# SGX530 register map
Vendor: Texas Instruments
Peripheral module from a debugger description file (folder am335x).
Registers are 32-bit, read-write, no defined reset value unless marked. A register's access mark holds for its fields unless they carry their own. Offsets are as the file gives them; lines under a group give offsets from that group; [hi:lo] are bit positions; {n}, {i} and the like mark numbered series; 'fields as' and 'values as' point back to an identical list; <NAME> marks a mode.

## SGX530 (part 1 of 2)
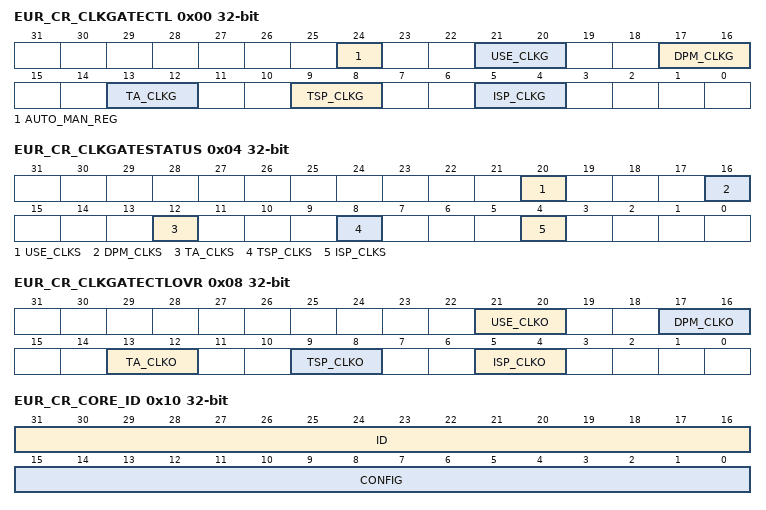
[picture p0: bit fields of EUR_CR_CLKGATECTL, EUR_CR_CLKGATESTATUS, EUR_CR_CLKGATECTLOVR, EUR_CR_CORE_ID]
0x00 EUR_CR_CLKGATECTL — Core module clock gating controls: allows clocks to be forced off, forced on or operate under automatic pipeline activity based clock gating.
  [24] AUTO_MAN_REG — Automatic Register Power Management Control
    0=Register updates automatically turn on clock domains; 1=Manual clock domain control for register updates
  [21:20] USE_CLKG — Clock gating control for the USSE
    0=Gated (Clock gating is active and no clock is supplied to the USSE); 1=Running (Clock to the USSE is enabled); 2=Automatic gating is active, the USSE clock is only active whilst data is being processed
  [17:16] DPM_CLKG — Clock gating control for the DPM
    0=Gated (Clock gating is active and no clock is supplied to the DPM); 1=Running (Clock to the DPM is enabled); 2=Automatic gating is active, the DPM clock is only active whilst data is being processed
  [13:12] TA_CLKG — Clock gating control for the TA
    0=Gated (Clock gating is active and no clock is supplied to the TA); 1=Running (Clock to the TA is enabled); 2=Automatic gating is active, the TA clock is only active whilst data is being processed
  [9:8] TSP_CLKG — Clock gating control for the TSP
    0=Gated (Clock gating is active and no clock is supplied to the TSP); 1=Running (Clock to the TSP is enabled); 2=Automatic gating is active, the TSP clock is only active whilst data is being processed
  [5:4] ISP_CLKG — Clock gating control for the ISP
    0=Gated (Clock gating is active and no clock is supplied to the ISP); 1=Running (Clock to the ISP is enabled); 2=Automatic gating is active, the ISP clock is only active whilst data is being processed
0x04 EUR_CR_CLKGATESTATUS ro — Clock Gating Status reflects the condition of the clock gate controls for each module.
  [20] USE_CLKS — Status of the USSE clock
    0=USSE (USSE clock is gated and the module is inactive); 1=Clock to the USSE is running
  [16] DPM_CLKS — Status of the DPM clock
    0=DPM (DPM clock is gated and the module is inactive); 1=Clock to the DPM is running
  [12] TA_CLKS — Status of the TA clock
    0=TA (TA clock is gated and the module is inactive); 1=Clock to the TA is running
  [8] TSP_CLKS — Status of the TSP clock
    0=TSP (TSP clock is gated and the module is inactive); 1=Clock to the TSP is running
  [4] ISP_CLKS — Status of the ISP clock
    0=ISP (ISP clock is gated and the module is inactive); 1=Clock to the ISP is running
0x08 EUR_CR_CLKGATECTLOVR — Core module clock gating override controls: allows clocks to be enabled temporarily for register writes by hosts.
  [21:20] USE_CLKO — Clock gating control override for the USSE
    1=Enabled (Host enable clock to the USSE request); 3=Disabled (Host disable clock to USSE request. USSE clock may be gated if not other outstanding host requests.)
  [17:16] DPM_CLKO — Clock gating control override for the DPM
    1=Enabled (Clock to the DPM is enabled); 3=Disabled (Host disable clock to DPM request. DPM clock may be gated if not other outstanding host requests.)
  [13:12] TA_CLKO — Clock gating control override for the TA
    1=Enabled (Clock to the TA is enabled); 3=Disabled (Host disable clock to TA request. TA clock may be gated if not other outstanding host requests.)
  [9:8] TSP_CLKO — Clock gating control override for the TSP
    1=Enabled (Clock to the TSP is enabled); 3=Disabled (Host disable clock to TSP request. TSP clock may be gated if no other outstanding host requests.)
  [5:4] ISP_CLKO — Clock gating control override for the ISP
    1=Enabled (Clock to the ISP is enabled); 3=Disabled (Host disable clock to ISP request. ISP clock may be gated if no other outstanding host requests.)
0x10 EUR_CR_CORE_ID ro — Core ID Register
  [31:16] ID — Core ID
  [15:0] CONFIG — Core Configuration
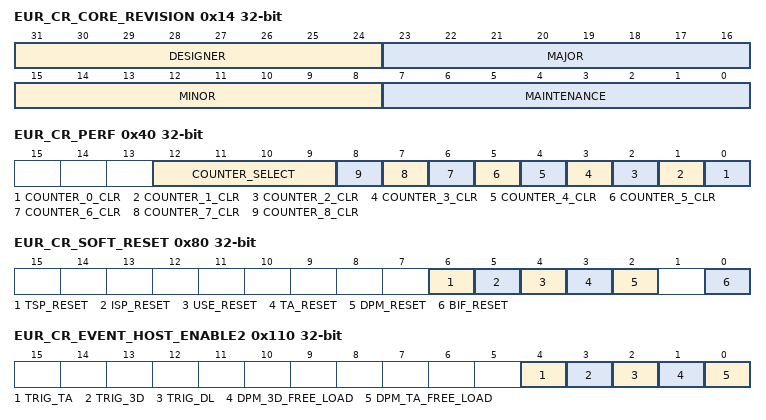
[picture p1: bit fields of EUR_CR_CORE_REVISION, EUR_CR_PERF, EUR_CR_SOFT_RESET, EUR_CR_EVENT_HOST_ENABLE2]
0x14 EUR_CR_CORE_REVISION ro — Core Revision Register identifies the specific core revision. This is updated to reflect the formal release status of the core.
  [31:24] DESIGNER
  [23:16] MAJOR — Major Revision
  [15:8] MINOR — Minor Revision
  [7:0] MAINTENANCE — Maintenance Revision
0x18 EUR_CR_DESIGNER_REV_FIELD1 ro — Designer Revision Field. The SOC designer can use this register for their own revision control if required.
  [31:0] DESIGNER_REV_FIELD1 — Designer Field
0x1C EUR_CR_DESIGNER_REV_FIELD2 ro — Designer Revision Field The SOC designer can use this register for their own revision control if required.
  [31:0] DESIGNER_REV_FIELD2 — Designer Field
0x40 EUR_CR_PERF — Within SGX there are a number of performance counters which enable profiling of an application in terms of the low level hardware performance; this register enables selection of specific groups of performance counters and the ability to reset those counters. Full details can be found in the performance profiling section of this document. Write a '1' followed by a '0' to the _CLR fields to reset the specific counter
  [12:9] COUNTER_SELECT — 0x0 Core Overview counter group. Default value is set to 0xF, no counter will be in operation
    1=Primitive Clipping counter group; 2=Scene Buffer counter group; 3=ISP (ISP counter group); 4=TSP (TSP counter group); 5=USE (USE counter group); 6=Texturing counter group; 9=Core Overview 2 counter group
  [n] COUNTER_{n}_CLR (n=0..8) — Reset counter = '1', normal counter operation '0'
{0x44+4i} EUR_CR_PERF_COUNTER{i} ro (i=0..7) — Performance counter {i} status register
  [31:0] COUNTER{i} — 32 bit integer count value, see performance profiling section for details
0x64 EUR_CR_PERF_COUNTER8 ro — Performance counter status register
  [31:0] COUNTER8 — 32 bit integer count value, see performance profiling section for details
0x80 EUR_CR_SOFT_RESET — Soft reset control register which drives all modules except the register bank. Write a '1' to reset and a '0' to clear
  [6] TSP_RESET — TSP soft reset control field
  [5] ISP_RESET — ISP soft reset control field
  [4] USE_RESET — USE soft reset control field
  [3] TA_RESET — TA soft reset control field
  [2] DPM_RESET — DPM soft reset control field
  [0] BIF_RESET — BIF soft reset control field
0x100 EUR_CR_TRIGGER — TA/3D Lockup counter timeout value (16K cycle granularity) (Debug only, for further information contact Imagination Technologies)
  [4:0] TRIGGER_COUNT — Trigger count value in 16K cycles for TA and 3D lockup triggers
0x110 EUR_CR_EVENT_HOST_ENABLE2 — This register enables interrupts. Writing a '1' to a bit field enables the relevant Event. All the bit fields correspond exactly to those in the EUR_CR_EVENT_STATUS2 register. The MASTER_INTERRUPT bit is a global enable which overrides the Event enables, i.e. '1' - enable external interrupts, '0' - disable external interrupts.
  [4] TRIG_TA — Host_Enable: Lockup in TA Phase Trigger
  [3] TRIG_3D — Host_Enable: Lockup in 3d Phase Trigger
  [2] TRIG_DL — Host_Enable: Deadlock has occurred after a Partial Render
  [1] DPM_3D_FREE_LOAD — Host_Enable: DPM 3D Free Load task complete
  [0] DPM_TA_FREE_LOAD — Host_Enable: DPM TA Free Load task complete
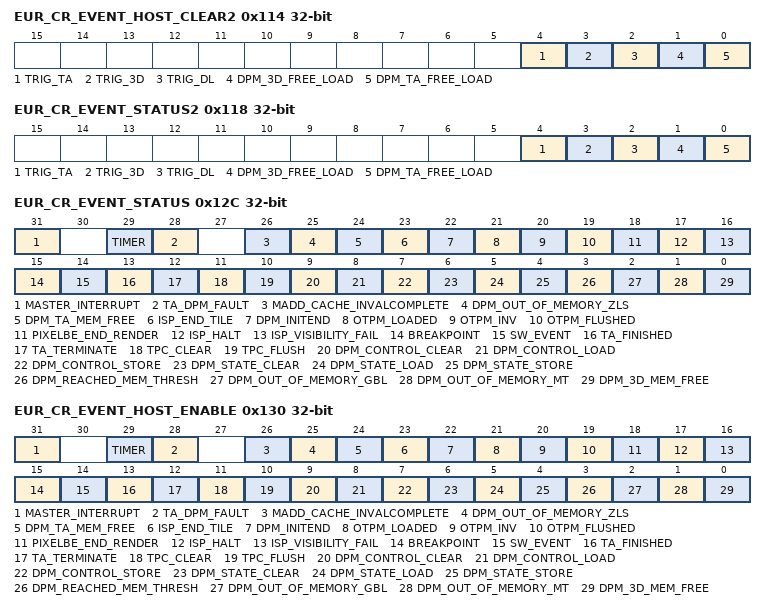
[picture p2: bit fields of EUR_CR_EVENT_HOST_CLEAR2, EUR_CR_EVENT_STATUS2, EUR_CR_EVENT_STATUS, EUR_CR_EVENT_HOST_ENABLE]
0x114 EUR_CR_EVENT_HOST_CLEAR2 wo — This register is used to clear event interrupts. Writing a '1' to a bit field clears the relevant Event. All the bit fields correspond exactly to those in the EUR_CR_EVENT_STATUS2 register.
  [4] TRIG_TA — Host_Clear: Lockup in TA Phase Trigger
  [3] TRIG_3D — Host_Clear: Lockup in 3d Phase Trigger
  [2] TRIG_DL — Host_Clear: Deadlock has occurred after a Partial Render
  [1] DPM_3D_FREE_LOAD — Host_Clear: DPM 3D Free Load task complete
  [0] DPM_TA_FREE_LOAD — Host_Clear: DPM TA Free Load task complete
0x118 EUR_CR_EVENT_STATUS2 — There are 2 sources of external interrupts in the PowerVR SGX core: General system events and PDS cache invalidation events. The event status2 register indicates the source of any general event interrupt generated by PowerVR SGX. These events only result in an external interrupt if the relevant bit in the EUR_CR_EVENT_HOST_ENABLE register is set. Note1: This register must be combined with the EUR_CR_PDS_CACHE_STATUS register information to determine what has caused the external interrupt. Note2: The host can write to this register in which case any bits written as a '1' are ORed into the register i.e. the host can cause the core to generate an interrupt. (This is typically for debug purposes only)
  [4] TRIG_TA — Status: Lockup in TA Phase Trigger
  [3] TRIG_3D — Status: Lockup in 3d Phase Trigger
  [2] TRIG_DL — Status: Deadlock has occurred after a Partial Render
  [1] DPM_3D_FREE_LOAD — Status: DPM 3D free load task complete
  [0] DPM_TA_FREE_LOAD — Status: DPM TA free load task complete
0x12C EUR_CR_EVENT_STATUS — There are 2 sources of external interrupts in the PowerVR SGX core: General system events and PDS cache invalidation events. The event status register indicates the source of any general event interrupt generated by PowerVR SGX. These events only result in an external interrupt if the relevant bit in the EUR_CR_EVENT_HOST_ENABLE register is set. Note1: This register must be combined with the EUR_CR_PDS_CACHE_STATUS register information to determine what has caused the external interrupt. Note2: The host can write to this register in which case any bits written as a '1' are ORed into the register i.e. the host can cause the core to generate an interrupt. (This is typically for debug purposes only)
  [31] MASTER_INTERRUPT — Status: PowerVR SGX Master Interrupt Control
  [29] TIMER — Status: The PDS Event timer interrupt (signalled on timer traversing through 0).
  [28] TA_DPM_FAULT — Status: The TA Object Passing System has got out of sync, a Terminate Control Word DPM read was met by StartofBlock data
  [26] MADD_CACHE_INVALCOMPLETE — Status: Invalidate of Madd L0, L1, L2 Cache Complete
  [25] DPM_OUT_OF_MEMORY_ZLS — Status: Memory Allocation Failed for ZLS
  [24] DPM_TA_MEM_FREE — Status: All memory associated with TA context has been freed
  [23] ISP_END_TILE — Status: ISP End tile
  [22] DPM_INITEND — Status: DPM Initialisation Complete
  [21] OTPM_LOADED — Status: The OTPM has loaded its state
  [20] OTPM_INV — Status: The OTPM has invalidated its contents
  [19] OTPM_FLUSHED — Status: The OTPM has flushed its state
  [18] PIXELBE_END_RENDER — Status: End of Scene
  [17] ISP_HALT — Status: ISP Halt breakpoint triggered
  [16] ISP_VISIBILITY_FAIL — Status: Visibility Test Fail
  [15] BREAKPOINT — Status: ISP Breakpoint
  [14] SW_EVENT — Status: Software triggered event
  [13] TA_FINISHED — Status: TA complete - This is set and held high after the TE terminates scene, until TA is restarted
  [12] TA_TERMINATE — Status: The TA terminate complete (issue as part of complex scene) - This is set and held high after the TE aborts a MacroTile after failed DPM allocation request, until TA is restarted
  [11] TPC_CLEAR — Status: The TPC has reset its state
  [10] TPC_FLUSH — Status: The TPC has stored its state
  [9] DPM_CONTROL_CLEAR — Status: The reset of the DPM control context has been completed
  [8] DPM_CONTROL_LOAD — Status: The load of the DPM control context has been completed
  [7] DPM_CONTROL_STORE — Status: The store of the DPM control context has been completed
  [6] DPM_STATE_CLEAR — Status: The reset of the DPM state context has been completed
  [5] DPM_STATE_LOAD — Status: The load of the DPM state context has been completed
  [4] DPM_STATE_STORE — Status: The store of the DPM state context has been completed
  [3] DPM_REACHED_MEM_THRESH — Status: DPM Memory allocation has reached the preset memory threshold for total memory allocation
  [2] DPM_OUT_OF_MEMORY_GBL — Status: DPM Memory allocation failed for the global list
  [1] DPM_OUT_OF_MEMORY_MT — Status: DPM Memory allocation failed for a macro tile
  [0] DPM_3D_MEM_FREE — Status: DPM Memory allocation complete for the current render
0x130 EUR_CR_EVENT_HOST_ENABLE — This register enables interrupts. Writing a '1' to a bit field enables the relevant Event. All the bit fields correspond exactly to those in the EUR_CR_EVENT_STATUS register. The MASTER_INTERRUPT bit is a global enable which overrides the Event enables, i.e. '1' - enable external interrupts, '0' - disable external interrupts.
  [31] MASTER_INTERRUPT — Host_Enable: PowerVR SGX Master Interrupt Control
  [29] TIMER — Host_Enable: The PDS Event timer interrupt (signalled on timer traversing through 0).
  [28] TA_DPM_FAULT — Host_Enable: The Tiling Co-Processor Object Passing System has got out of sync, a Terminate Control Word DPM read was met by StartofBlock data
  [26] MADD_CACHE_INVALCOMPLETE — Host_Enable: Invalidate of Madd L0, L1, L2 Cache Complete
  [25] DPM_OUT_OF_MEMORY_ZLS — Host_Enable: Memory Allocation Failed for ZLS
  [24] DPM_TA_MEM_FREE — Host_Enable: All memory associated with TA context has been freed
  [23] ISP_END_TILE — Host_Enable: ISP End tile
  [22] DPM_INITEND — Host_Enable: DPM Initialisation Complete
  [21] OTPM_LOADED — Host_Enable: The OTPM has loaded its state
  [20] OTPM_INV — Host_Enable: The OTPM has invalidated its contents
  [19] OTPM_FLUSHED — Host_Enable: The OTPM has flushed its state
  [18] PIXELBE_END_RENDER — Host_Enable: End of Scene
  [17] ISP_HALT — Host_Enable: ISP Halt breakpoint triggered
  [16] ISP_VISIBILITY_FAIL — Host_Enable: Visibility Test Fail
  [15] BREAKPOINT — Host_Enable: ISP Breakpoint
  [14] SW_EVENT — Host_Enable: Software triggered event
  [13] TA_FINISHED — Host_Enable: Tiling Co-Processor complete, (Scene Terminated)
  [12] TA_TERMINATE — Host_Enable: The Tiling Co-Processor terminate complete (issue as part of complex scene) (MacroTile Aborted)
  [11] TPC_CLEAR — Host_Enable: The TPC has reset its state
  [10] TPC_FLUSH — Host_Enable: The TPC has stored its state
  [9] DPM_CONTROL_CLEAR — Host_Enable: The reset of the DPM control context has been completed
  [8] DPM_CONTROL_LOAD — Host_Enable: The load of the DPM control context has been completed
  [7] DPM_CONTROL_STORE — Host_Enable: The store of the DPM control context has been completed
  [6] DPM_STATE_CLEAR — Host_Enable: The reset of the DPM state context has been completed
  [5] DPM_STATE_LOAD — Host_Enable: The load of the DPM state context has been completed
  [4] DPM_STATE_STORE — Host_Enable: The store of the DPM state context has been completed
  [3] DPM_REACHED_MEM_THRESH — Host_Enable: DPM Memory allocation has reached the preset memory threshold for total memory allocation
  [2] DPM_OUT_OF_MEMORY_GBL — Host_Enable: DPM Memory allocation failed for the global list
  [1] DPM_OUT_OF_MEMORY_MT — Host_Enable: DPM Memory allocation failed for a macro tile
  [0] DPM_3D_MEM_FREE — Host_Enable: DPM Memory allocation complete for the current render
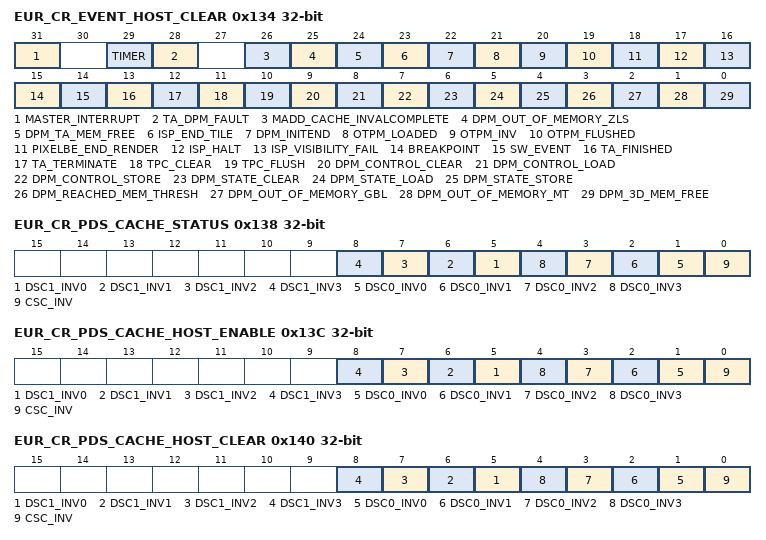
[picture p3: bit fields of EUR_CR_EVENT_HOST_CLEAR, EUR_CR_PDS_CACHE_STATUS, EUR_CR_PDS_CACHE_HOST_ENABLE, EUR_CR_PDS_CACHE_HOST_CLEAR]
0x134 EUR_CR_EVENT_HOST_CLEAR — This register is used to clear event interrupts. Writing a '1' to a bit field clears the relevant Event. All the bit fields correspond exactly to those in the EUR_CR_EVENT_STATUS register.
  [31] MASTER_INTERRUPT — Host_Clear: PowerVR SGX Master Interrupt
  [29] TIMER — Host_Clear: The PDS Event timer interrupt (signalled on timer traversing through 0).
  [28] TA_DPM_FAULT — Host_Clear: The TA Object Passing System has got out of sync, a Terminate Control Word DPM read was met by StartofBlock data
  [26] MADD_CACHE_INVALCOMPLETE — Host_Clear: Invalidate of Madd L1, L2 Cache Complete
  [25] DPM_OUT_OF_MEMORY_ZLS — Host_Clear: Memory Allocation Failed for ZLS
  [24] DPM_TA_MEM_FREE — Host_Clear: All memory associated with TA context has been freed
  [23] ISP_END_TILE — Host_Clear: ISP End tile
  [22] DPM_INITEND — Host_Clear: DPM Initialisation Complete
  [21] OTPM_LOADED — Host_Clear: The OTPM has loaded its state
  [20] OTPM_INV — Host_Clear: The OTPM has invalidated its contents
  [19] OTPM_FLUSHED — Host_Clear: The OTPM has flushed its state
  [18] PIXELBE_END_RENDER — Host_Clear: End of Scene
  [17] ISP_HALT — Host_Clear: ISP Halt breakpoint triggered
  [16] ISP_VISIBILITY_FAIL — Host_Clear: Visibility Test Fail
  [15] BREAKPOINT — Host_Clear: ISP Breakpoint
  [14] SW_EVENT — Host_Clear: Software triggered event
  [13] TA_FINISHED — Host_Clear: Tiling Co-Processor complete (Scene Terminated)
  [12] TA_TERMINATE — Host_Clear: The Tiling Co-Processor terminate complete (issue as part of complex scene) (MacroTile aborted)
  [11] TPC_CLEAR — Host_Clear: The TPC has reset its state
  [10] TPC_FLUSH — Host_Clear: The TPC has stored its state
  [9] DPM_CONTROL_CLEAR — Host_Clear: The reset of the DPM control context has been completed
  [8] DPM_CONTROL_LOAD — Host_Clear: The load of the DPM control context has been completed
  [7] DPM_CONTROL_STORE — Host_Clear: The store of the DPM control context has been completed
  [6] DPM_STATE_CLEAR — Host_Clear: The reset of the DPM state context has been completed
  [5] DPM_STATE_LOAD — Host_Clear: The load of the DPM state context has been completed
  [4] DPM_STATE_STORE — Host_Clear: The store of the DPM state context has been completed
  [3] DPM_REACHED_MEM_THRESH — Host_Clear: DPM Memory allocation has reached the preset memory threshold for total memory allocation
  [2] DPM_OUT_OF_MEMORY_GBL — Host_Clear: DPM Memory allocation failed for the global list
  [1] DPM_OUT_OF_MEMORY_MT — Host_Clear: DPM Memory allocation failed for a macro tile
  [0] DPM_3D_MEM_FREE — Host_Clear: DPM Memory allocation complete for the current render
0x138 EUR_CR_PDS_CACHE_STATUS — There are 2 sources of external interrupts in the PowerVR SGX core: General system events and PDS cache invalidation events. The PDS cache status register indicates the source of any PDS cache invalidation event interrupts generated by PowerVR SGX. These events only result in an external interrupt if the relevant bit in the EUR_CR_PDS_CACHE_HOST_ENABLE register is set. Note1: This register must be combined with the EUR_CR_EVENT_STATUS register information to determine what has caused the external interrupt. Note2: The host can write to this register in which case any bits written as a '1' are ORed into the register i.e. the host can cause the core to generate an interrupt. (This is typically for debug purposes only)
  [n+5] DSC1_INV{n} (n=0..3) — Status: Context ID {n} has been invalidated in PDS Data Store Cache 1
  [n+1] DSC0_INV{n} (n=0..3) — Status: Context ID {n} has been invalidated in PDS Data Store Cache 0
  [0] CSC_INV — Status: PDS Code Store Cache has been invalidated
0x13C EUR_CR_PDS_CACHE_HOST_ENABLE — This register enables interrupts. Writing a '1' to a bit field enables the relevant Event. All the bit fields correspond exactly to those in the EUR_CR_PDS_CACHE_STATUS register. The MASTER_INTERRUPT bit contained in the EUR_CR_EVENT_HOST_ENABLE register is a global enable which overrides the Event enables, i.e. '1' - enable external interrupts, '0' - disable external interrupts.
  [n+5] DSC1_INV{n} (n=0..3) — Host_Enable: Context ID {n} has been invalidated in PDS Data Store Cache 1
  [n+1] DSC0_INV{n} (n=0..3) — Host_Enable: Context ID {n} has been invalidated in PDS Data Store Cache 0
  [0] CSC_INV — Host_Enable: PDS Code Store Cache has been invalidated
0x140 EUR_CR_PDS_CACHE_HOST_CLEAR — This register is used to clear event interrupts. Writing a '1' to a bit field clears the relevant Event. All the bit fields correspond exactly to those in the EUR_CR_PDS_CACHE_STATUS register.
  [n+5] DSC1_INV{n} (n=0..3) — Host_Clear: Context ID {n} has been invalidated in PDS Data Store Cache 1
  [n+1] DSC0_INV{n} (n=0..3) — Host_Clear: Context ID {n} has been invalidated in PDS Data Store Cache 0
  [0] CSC_INV — Host_Clear: PDS Code Store Cache has been invalidated
0x200 EUR_CR_VDM_START wo — Any write to this register starts the Vertex Data Master DMA operation
  [0] PULSE — Start VDM DMA
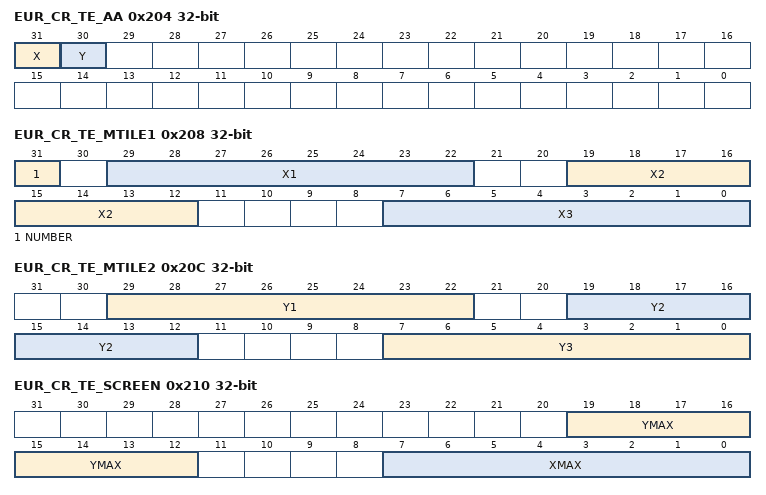
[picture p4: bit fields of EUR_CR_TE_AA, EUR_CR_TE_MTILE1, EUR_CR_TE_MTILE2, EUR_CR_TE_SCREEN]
0x204 EUR_CR_TE_AA — This register controls the anti-aliasing mode of the Tiling Co-Processor, independent control is provided in both X & Y axis.
  [31] X — Anti-Aliasing in X:
    0=No (No Anti-Aliasing on X plane); 1=Yes (Anti-Aliasing on X plane)
  [30] Y — Anti-Aliasing in Y:
    0=No (No Anti-Aliasing on Y plane); 1=Yes (Anti-Aliasing on Y plane)
0x208 EUR_CR_TE_MTILE1 — The Tiling Co-Processor allocates memory in macrotiles, which is a group of individual tiles. The number of macrotiles is selectable between 4 & 16, the boundaries of the macrotiles in the X axis are defined in this register.
  [31] NUMBER — PSG_MacroTile_Number:
    0=4 MacroTiles; 1=16 MacroTiles
  [29:22] X1 — X1 MacroTile boundary, left tile X for second column of macrotiles (16MT mode)
  [19:12] X2 — X2 MacroTile boundary, left tile X for second(4MT)/third(16MT) column of macrotiles
  [7:0] X3 — X3 MacroTile boundary, left tile X for fourth column of macrotiles (16MT)
0x20C EUR_CR_TE_MTILE2 — The Tiling Co-Processor allocates memory in macrotiles, which is a group of individual tiles. The number of macrotiles is selectable between 4 & 16, the boundaries of the macrotiles in the Y axis are defined in this register.
  [29:22] Y1 — Y1 MacroTile boundary, top tile Y for second row of macrotiles (16MT mode)
  [19:12] Y2 — Y2 MacroTile boundary, top tile Y for second(4MT)/third(16MT) row of macrotiles
  [7:0] Y3 — Y1 MacroTile boundary, top tile Y for fourth row of macrotiles (16MT mode)
0x210 EUR_CR_TE_SCREEN — In order to perform the tiling operation and generate the display list the maximum screen size must be configured in terms of the number of tiles in X & Y axis.
  [19:12] YMAX — Maximum Y tile address visible on screen
  [7:0] XMAX — Maximum X tile address visible on screen
0x214 EUR_CR_TE_MTILE — This register defines the number of individual tiles within the macrotiles. This is used in the process of memory allocation.
  [17:0] STRIDE — Number of tiles in a Macrotile. Stride = (XTile * YTiles)
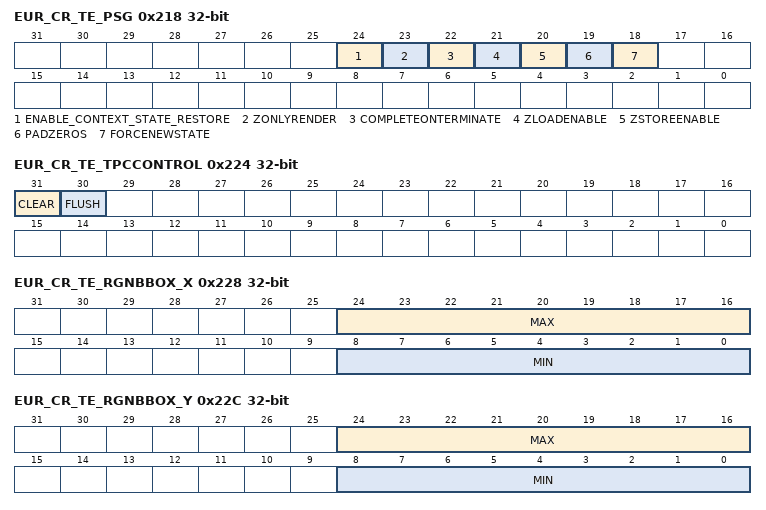
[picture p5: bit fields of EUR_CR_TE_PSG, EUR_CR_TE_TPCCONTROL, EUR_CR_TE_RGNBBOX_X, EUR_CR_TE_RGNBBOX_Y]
0x218 EUR_CR_TE_PSG — This register defines the global control for the Parameter Stream Generator within the Tiling Co-Processor. This module formats the display list generated by the Tiling Co-Processor.
  [24] ENABLE_CONTEXT_STATE_RESTORE — Enables sampling of Driver TE_STATE_ISP_STATE_ID register on context switch/restore when set, when reset current local value is preserved.
  [23] ZONLYRENDER — Don't invalidate Tail Pointer Cache entries on a Terminate command. Only effective when COMPLETEONTERMINATE is 0x0
    0=Do (Do Invalidate); 1=Don (Don't Invalidate)
  [22] COMPLETEONTERMINATE — 0x1 Write region headers, terminate streams and invalidate tail pointer cache entries on terminate.
    0=If (If ZONLYRENDER = 0x0 then force an Interrupt, however if ZONLYRENDER = 0x1 then write region headers and terminate streams.)
  [21] ZLOADENABLE — If 0x1 set the zload enable bit in the region headers. If 0x0 the region header zload bit is controlled by the hardware automatically. The bit is set if a partial render has been performed on that tile.
  [20] ZSTOREENABLE — If 0x1 set the zstore enable bit in the region headers. If 0x0 the region header zstore bit is controlled by the hardware automatically. The bit is set if a partial render is about to be performed on that tile.
  [19] PADZEROS — Pad empty doublewords in allocation with zeros after Stream Link/Terminate. The allocation block size is 16 DWords, so potentially inserts 13 extra DWords of zeros into a pointer block. Debug only. Makes examination of memory more readable on a per frame basis.
  [18] FORCENEWSTATE — Always embed state information in control stream. Debug only.
0x21C EUR_CR_TE_PSGREGION_BASE — This register defines the base address in memory of the Region Header writes by the TA. Region headers are the first part of the display list and contain an entry per tile with information on global setup and a link address to parameters.
  [27:6] ADDR — 256MB Addressable, 512-bit aligned Base Address for Region Header writes
0x220 EUR_CR_TE_TPC_BASE — This register defines the base address in memory of the Tail Pointer Cache. A tail pointer is the current last address written to for a tiles individual display list, an entry for active tiles is maintained as primitives are processed by the TA.
  [27:6] ADDR — 256MB Addressable, 512-bit aligned Base Address for Tail Pointer Cache. The tail pointer is the current last address written to for a control stream for a tile.
0x224 EUR_CR_TE_TPCCONTROL wo — The Tail Pointer Cache is used to keep track of the last address written to for a particular tile, this is stored in a mixture of on chip cache and external memory. Under certain circumstances it is necessary to either reset the cache or flush the on chip cache contents such that they are visible in memory.
  [31] CLEAR — Reset contents of Tail Pointer Cache
  [30] FLUSH — Flush contents of Tail Pointer Cache to Memory
0x228 EUR_CR_TE_RGNBBOX_X ro — Reset or enabled by the MTE_RESETBBOX and MTE_UPDATEBBOX fields in the MTEControl word of the Input Parameter format. This is the maximum extent in X of the post transformed, clipped data before region clipping.
  [24:16] MAX — XMax value for maintained Region Generator Bounding Box
  [8:0] MIN — XMin value for maintained Region Generator Bounding Box
0x22C EUR_CR_TE_RGNBBOX_Y ro — Reset or enabled by the MTE_RESETBBOX and MTE_UPDATEBBOX fields in the MTE Control word of the Input Parameter format. This is the maximum extent in Y of the post transformed, clipped data before region clipping.
  [24:16] MAX — YMax value for maintained Region Generator Bounding Box
  [8:0] MIN — YMin value for maintained Region Generator Bounding Box
0x230 EUR_CR_MTE_OTPM_CSM_FLUSH_BASE — The TA maintains internal state of the current information for each macro tile and global list regarding the vertex blocks written to memory. In certain circumstances during a context switch it is necessary to flush this information to external memory.
  [27:4] ADDR — 256MB Addressable, 512-bit aligned Base Address for Object Tail Pointer Memory Context Switchable Memory (OTPM CSM) Flush. This is the current point for each macro tile and global list, for the vertex blocks written to memory by the Tile Accelerator.
0x234 EUR_CR_MTE_OTPM_CSM_LOAD_BASE — The TA maintains internal state of the current information for each macro tile and global list regarding the vertex blocks written to memory. In certain circumstances during a context switch it is necessary to load this information from external memory.
  [27:4] ADDR — 256MB Addressable, 512-bit aligned Base Address for Object Tail Pointer Memory Context Switchable Memory (OTPM CSM) Load. This is the current point for each macro tile and global list, for the vertex blocks written to memory by the Tile Accelerator.
0x238 EUR_CR_VDM_CTRL_STREAM_BASE — PowerVR SGX masters information from memory using advanced DMA, this register defines the base address of the Vertex Data input control stream in memory.
  [27:2] ADDR — 256MB Addressable, byte aligned Base Address for Vertex Data control streams
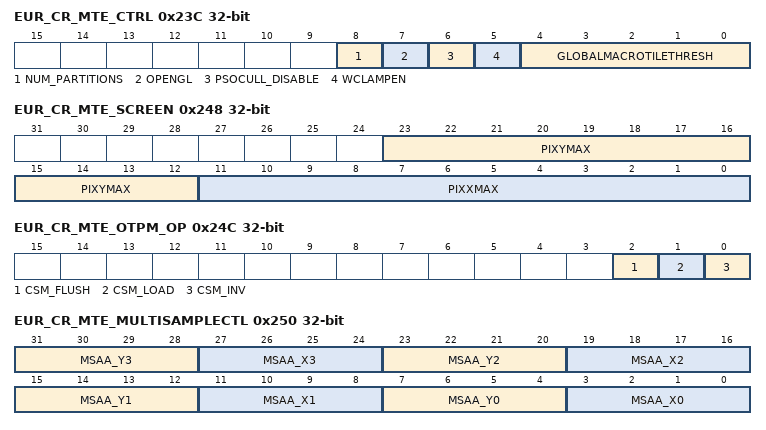
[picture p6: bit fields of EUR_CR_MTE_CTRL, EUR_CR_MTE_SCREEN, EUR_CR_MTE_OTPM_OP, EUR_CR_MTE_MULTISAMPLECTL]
0x23C EUR_CR_MTE_CTRL — This register controls the global setup of the Tiling Process.
  [8] NUM_PARTITIONS — Maximum number of partitions which can be used per USSE pipeline:
    0=Two; 1=Four
  [7] OPENGL — Select OpenGL or D3D mode
    0=D3D; 1=OpenGL
  [6] PSOCULL_DISABLE — Disable for perfect small object culling
    0=en (Perfect small object culling enabled); 1=dis (Perfect small object culling disabled)
  [5] WCLAMPEN — Enable W clamping
    0=dis (W clamping disabled); 1=en (W clamping enabled)
  [4:0] GLOBALMACROTILETHRESH — When writing to global list, number of primitives which are within the same macrotile before the macrotile calculation will change from global.
0x240 EUR_CR_MTE_WCOMPARE
  [31:0] VALUE — Compare value for W clamping. See the Input parameter format, viewport transform for details. Compare is applied post viewport transform.
0x244 EUR_CR_MTE_WCLAMP
  [31:0] VALUE — Clamp value for W clamping. See the Input parameter format, viewport transform for details. Clamp is applied post viewport transform, if the w value is less than the WCOMPARE value.
0x248 EUR_CR_MTE_SCREEN — In order to perform the tiling operation and generate the display list the maximum screen size must be configured in terms of the number of pixels in X & Y axis since this may not be the same as the number of tiles defined in the EUR_CR_TE_SCREEN register.
  [23:12] PIXYMAX — Screen height in pixels.
  [11:0] PIXXMAX — Screen width in pixels.
0x24C EUR_CR_MTE_OTPM_OP wo — The TA maintains internal state of the current information for each macro tile and global list regarding the vertex blocks written to memory. In certain circumstances during a context switch it is necessary to load or flush this information to external memory.
  [2] CSM_FLUSH — Flush CSM contents to CSM Flush Address
  [1] CSM_LOAD — Load CSM contents from CSM Load Address
  [0] CSM_INV — Invalidate CSM contents
0x250 EUR_CR_MTE_MULTISAMPLECTL — This applies when anti-aliasing is enabled. This is used to calculate whether an anti-aliased triangle can be perfect small object culled.
  [31:28] MSAA_Y3 — Unsigned sub-pixel offset for the 4th multisample Y position
  [27:24] MSAA_X3 — Unsigned sub-pixel offset for the 4th multisample X position
  [23:20] MSAA_Y2 — Unsigned sub-pixel offset for the 3rd multisample Y position
  [19:16] MSAA_X2 — Unsigned sub-pixel offset for the 3rd multisample X position
  [15:12] MSAA_Y1 — Unsigned sub-pixel offset for the 2nd multisample Y position
  [11:8] MSAA_X1 — Unsigned sub-pixel offset for the 2nd multisample X position
  [7:4] MSAA_Y0 — Unsigned sub-pixel offset for the 1st multisample Y position
  [3:0] MSAA_X0 — Unsigned sub-pixel offset for the 1st multisample X position
0x26C EUR_CR_MTE_SIG1 ro
  [31:0] TE_SIGNATURE — Signature of output to TE. A signature is an accumulative LFSR (Linear Feedback Shift Register) of the valid pipeline data using an XOR structure.
0x270 EUR_CR_MTE_SIG2 ro
  [31:0] MEM_SIGNATURE — Signature of output to memory. A signature is an accumulative LFSR (Linear Feedback Shift Register) of the valid pipeline data using an XOR structure.
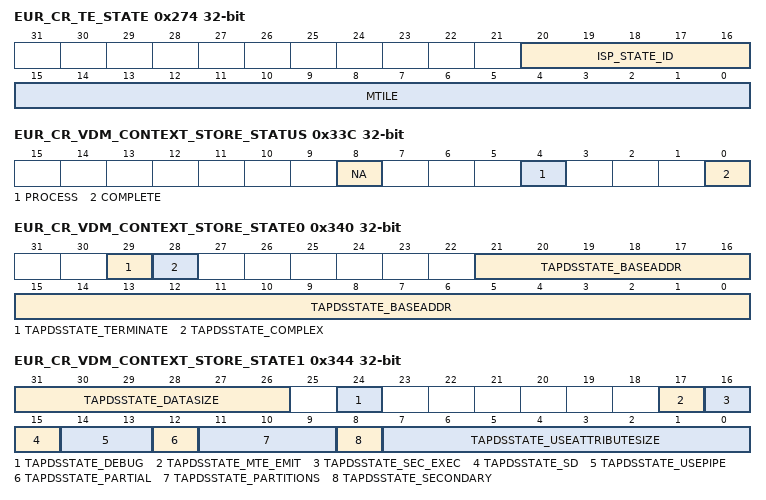
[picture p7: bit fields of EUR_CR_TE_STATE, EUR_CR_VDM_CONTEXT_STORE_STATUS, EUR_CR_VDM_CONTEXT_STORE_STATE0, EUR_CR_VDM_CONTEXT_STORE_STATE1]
0x274 EUR_CR_TE_STATE — This register is read on VDM_START_PULSE and should be saved and updated by the driver app by app
  [20:16] ISP_STATE_ID — This register contains the PSG internal ISP State ID Counter value. It must be saved off by the driver on TA terminate or finished and restored before vdm_start_pulse.
  [15:0] MTILE — A read of this register returns the page allocated to the host, when valid. If it is not valid the return data is undefined.
0x304 EUR_CR_CLIP_SIG1 ro
  [31:0] CLIP_SIGNATURE — Signature of Barycentric vertices output during each clipping pass i.e. clipped against each clip plane in turn. A signature is an accumulative LFSR (Linear Feedback Shift Register) of the valid pipeline data using an XOR structure.
0x308 EUR_CR_PIXELBE_SIG01 ro
  [31:0] SIGNATURE — Signature of data output from PBE to BIF. A signature is an accumulative LFSR (Linear Feedback Shift Register) of the valid pipeline data using an XOR structure.
0x30C EUR_CR_PIXELBE_SIG02 ro
  [31:0] SIGNATURE — Signature of control data output from PBE to BIF. A signature is an accumulative LFSR (Linear Feedback Shift Register) of the valid pipeline data using an XOR structure.
0x330 EUR_CR_VDM_CONTEXT_STORE_START — Start VDM Context store, pulse kicks off the store operation. Status flags when this is complete and the stream and index position registers are valid
  [0] PULSE — Start VDM Context store
0x334 EUR_CR_VDM_CONTEXT_STORE_STREAM ro — Stores the stream position when the context store occured
  [27:2] ADDR — stream position for context store, number of 32bit dwords from a base address update (ie. between stream link or terminates)
0x338 EUR_CR_VDM_CONTEXT_STORE_INDEX ro — Stores the index position when the context store occured
  [21:0] ADDR — Index position for context store, number of index words from an index define
0x33C EUR_CR_VDM_CONTEXT_STORE_STATUS ro — Signals when a context store is complete and the stream and index location registers are valid
  [8] NA — Context store not applicable doing a stream terminate
  [4] PROCESS — Context store processing
  [0] COMPLETE — Context store complete
0x340 EUR_CR_VDM_CONTEXT_STORE_STATE0 — Terminate state control registers used for creating the terminate PDS task.
  [29] TAPDSSTATE_TERMINATE — defines the last word in the control stream, used to generate end ta
  [28] TAPDSSTATE_COMPLEX — defines if the state update is complex
  [21:0] TAPDSSTATE_BASEADDR — Base address (128Bit Aligned, 256 MByte range), in 16 byte units of the PDS code and data to be executed
0x344 EUR_CR_VDM_CONTEXT_STORE_STATE1 — Terminate state control registers used for creating the terminate PDS task.
  [31:26] TAPDSSTATE_DATASIZE — Size of the PDS Data segment in 128 bit words. The data segment always precedes the code segment. 0 = 0x0, Max = 0x20
  [24] TAPDSSTATE_DEBUG — Enables breakpoints on this program
  [17] TAPDSSTATE_MTE_EMIT — If set the USSE will output state to the MTE
  [16] TAPDSSTATE_SEC_EXEC — 0 ' Do not execute secondary task on the USSE/1 ' Execute secondary task on the USSE Has no effect on primary tasks.
  [15] TAPDSSTATE_SD — Indicates a sequential dependency
  [14:13] TAPDSSTATE_USEPIPE — 0 ' Reserved/1 ' Run on pipe 1/2 ' Run on pipe 2/3 ' Run on both pipes
  [12] TAPDSSTATE_PARTIAL — Indicates partial secondary updates.
  [11:9] TAPDSSTATE_PARTITIONS — Number of output partitions required. 0 = 0x0 and Max = 0x4
  [8] TAPDSSTATE_SECONDARY — Indicates that the allocation is secondary
  [7:0] TAPDSSTATE_USEATTRIBUTESIZE — Size of the USSE Attribute Requirements for the task in 128 bit Words
0x348 EUR_CR_VDM_WAIT_FOR_KICK ro — Indicates the status on the control stream fetch
  [0] STATUS — Indicates when state machine is in idle
0x34C EUR_CR_VDM_CONTEXT_STORE_WRAP_INDEX ro — Stores the number of indices since the last wrap
  [21:0] COUNT — Wrap Index Count for context store, number of indices since last wrap
0x350 EUR_CR_VDM_CONTEXT_STORE_WRAPPED ro — Indicates the number of times that index wrapping has occurred after a context store
  [21:0] COUNT — Wrapped count for context store, number of times the hardware has wrapped after a context store
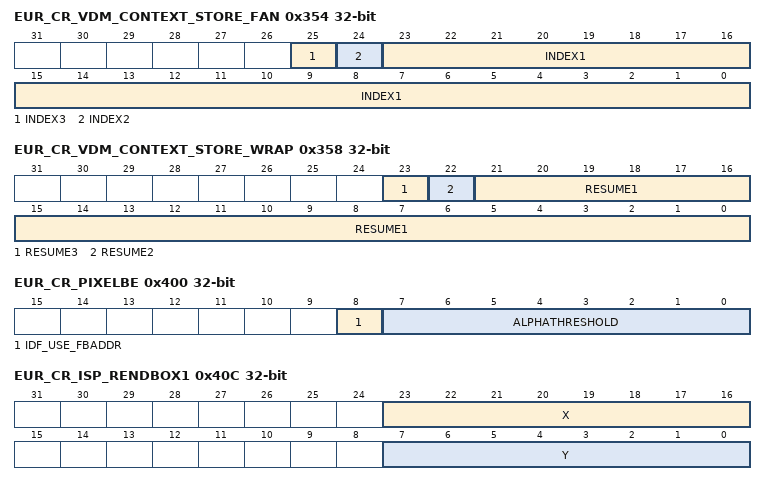
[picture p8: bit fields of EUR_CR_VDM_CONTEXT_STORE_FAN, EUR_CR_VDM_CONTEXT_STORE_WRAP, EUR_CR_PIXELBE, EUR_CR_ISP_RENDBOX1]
0x354 EUR_CR_VDM_CONTEXT_STORE_FAN — The driver sets this register on a context switch such that the hardware can resume knowing where the centre point of a fan is located or the winding order of the strip, expressed as an index.
  [25] INDEX3 — Controls setting of the winding order for the primitive about to be resumed
  [24] INDEX2 — An enable bit, ‘1’ = valid and triggers the use of the index indicated in bits 23:0. (Valid only on a VDM_START_PULSE)
  [23:0] INDEX1 — Context store, index to be used as center point to Fan after a context store.
0x358 EUR_CR_VDM_CONTEXT_STORE_WRAP — Indicates the number of times that index wrapping has occurred after a context store
  [23] RESUME3 — Indicates control of the value to be used in the next index block (‘1’ = context wrap counter + 1,’0’ = reset context wrap counter)
  [22] RESUME2 — An enable bit, ‘1’ = valid and triggers the use of the wrap count value indicated in bits 21:0. (Valid only on a VDM_START_PULSE)
  [21:0] RESUME1 — Context store, wrap counter value used on a resume
0x400 EUR_CR_PIXELBE — The PixelBE modules format the pixel data before writing to memory, this register contains global control signals.
  [8] IDF_USE_FBADDR — Use Frame buffer address for IDF's when set to 1. Default is 0 which means IDFs use the last address written too by the PBE
  [7:0] ALPHATHRESHOLD — Alpha threshold used when encoding 1555 format. If the internal 8bit Alpha value exceeds this value, then a 1 is written to the top bit of the output, otherwise a 0 is written
0x404 EUR_CR_ISP_RENDER — The Image Synthesis Processor can be configured to operate in 3 different render modes
  [1:0] TYPE — Render type
    0=3D_0 (= Normal 3D render); 1=3D_1 (= Normal 3D render); 2=2D (= Fast 2D render); 3=Scale (= Fast scale render)
0x408 EUR_CR_ISP_RGN_BASE — This register defines the base address in memory of the Region Header reads by the ISP. Region headers are the first part of the display list and contain an entry per tile with information on global setup and a link address to parameters.
  [27:2] ADDR — 256MB Addressable, Dword aligned Base Address for Region Header Reads
0x40C EUR_CR_ISP_RENDBOX1 — When the render type is set to Fast 2D Render or Fast Scale Render, no region headers are read from memory. Instead, region headers are internally generated for all tiles enclosed in the bounding box defined by this register and the EUR_CR_ISP_RENDBOX2 register.
  [23:16] X — Bounding box X1. X address, in tiles, of top left most tile in bounding box. The LSB is ignored if AA_MODE is low.
  [7:0] Y — Bounding box Y1. Y address, in tiles, of top left most tile in bounding box. The LSB is ignored if AA_MODE is low.
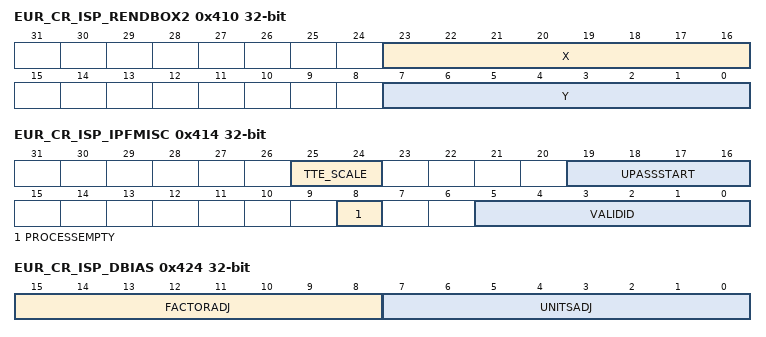
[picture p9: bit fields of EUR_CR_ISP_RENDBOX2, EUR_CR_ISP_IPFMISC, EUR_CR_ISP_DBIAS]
0x410 EUR_CR_ISP_RENDBOX2 — When the render type is set to Fast 2D Render or Fast Scale Render, no region headers are read from memory. Instead, region headers are internally generated for all tiles enclosed in the bounding box defined by this register and the EUR_CR_ISP_RENDBOX1 register.
  [23:16] X — Bounding box X2. X address, in tiles, of bottom right most tile in bounding box. The LSB is ignored if AA_MODE is low.
  [7:0] Y — Bounding box Y2. Y address, in tiles, of bottom right most tile in bounding box.The LSB is ignored if AA_MODE is low.
0x414 EUR_CR_ISP_IPFMISC — Global control register for the ISP parameter fetch.
  [25:24] TTE_SCALE — Scale factor for ISP parameter fetch to BIF TTE.
  [19:16] UPASSSTART — Initial upass_ctrl value, loaded at the start of each tile, for user pass spawning in the ISP.
  [8] PROCESSEMPTY — If this bit is set, all empty regions encountered will be processed by the 3D core ie the hardware background object being rendered in each empty tile. NOTE that this bit does not affect a "Fast Scale Render" i.e. empty regions are always processed when performing a "Fast Scale Render".
  [5:0] VALIDID — 6 bit field specify the minimum object ID required for opaque and translucent objects to be rendered.
0x418 EUR_CR_ISP_OGL_MODE — Global control register which modifies the pixel sample position to comply with OGL requirements.
  [0] ENABLE — 0 Non OGL Rules
    0=Disabled (Non OGL Rules); 1=Enabled (OGL Rules)
0x41C EUR_CR_ISP_PERPENDICULAR
  [30:4] THRESHOLD — If the determinant in the ISP FPU is smaller than this unsigned float, then perpendicular maths is used.
0x420 EUR_CR_ISP_CULLVALUE
  [30:4] THRESHOLD — If the determinant in the ISP FPU is smaller than this unsigned float, then the triangle is culled.
0x424 EUR_CR_ISP_DBIAS
  [15:8] FACTORADJ — Signed 2's complement integer used to control the slope dependent part of depth bias. The default value should be -23.
  [7:0] UNITSADJ — Signed 2's complement integer used to control the slope independent part of depth bias. The default value should be 0.
0x428 EUR_CR_ISP_START_RENDER wo — Any write to this register starts a 3D Render.
  [0] PULSE — Start 3D render
0x42C EUR_CR_3D_AA_MODE — Indicates to the 3D pipeline whether anti-aliasing is enabled or disabled
  [0] ENABLE
    0=Disabled (anti aliasing disabled); 1=Enabled (anti aliasing enabled)
